# PIC32CM6408PL10048 device description
Architecture: CORTEX-M0PLUS; Family: PIC32CMPL; Series: PIC32CMPL10
Registers are 32-bit, read-write, reset 0x0 unless marked. A register's access mark holds for its fields unless they carry their own. Offsets are from the block's base; [hi:lo] are bit positions; lines under a group give offsets from that group; {n}, {i} and the like mark numbered series; 'fields as' and 'values as' point back to an identical list.

## PM — Power Manager
Instances: PM 0x40000400
0x04 SLEEPCFG — Sleep Configuration
  [2:0] SLEEPMODE
    2=IDLE (Idle sleep mode enabled); 4=STANDBY (Standby sleep mode enabled)
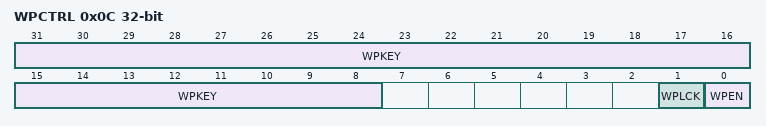
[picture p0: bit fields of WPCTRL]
0x0C WPCTRL — Write Protection Control
  [31:8] WPKEY — Write Protection Key
    0x505752=KEY (Allow writes to the WPCTRL register)
  [1] WPLCK — Write Protection Lock
  [0] WPEN — Write Protection Enable

## PORT — I/O Pin Controller
Instances: PORT 0x41000000, PORT_IOBUS 0x50000000
{0x0+0x80*i} GROUP[{i}] (i=0..1) group
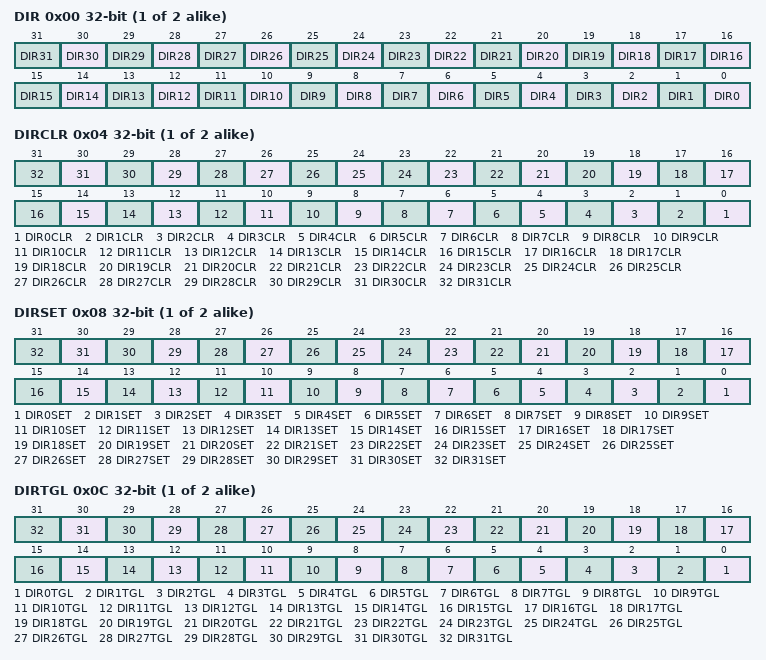
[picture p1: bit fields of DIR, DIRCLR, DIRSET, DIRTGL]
  0x00 DIR — Data Direction
    [n] DIR{n} (n=0..31) — Port Data Direction {n}
  0x04 DIRCLR (atomic clear of DIR) — Data Direction Clear
    [n] DIR{n}CLR (n=0..31) — Port Data Direction {n} Clear
  0x08 DIRSET (atomic set of DIR) — Data Direction Set
    [n] DIR{n}SET (n=0..31) — Port Data Direction {n} Set
  0x0C DIRTGL (atomic toggle of DIR) — Data Direction Toggle
    [n] DIR{n}TGL (n=0..31) — Port Data Direction {n} Toggle
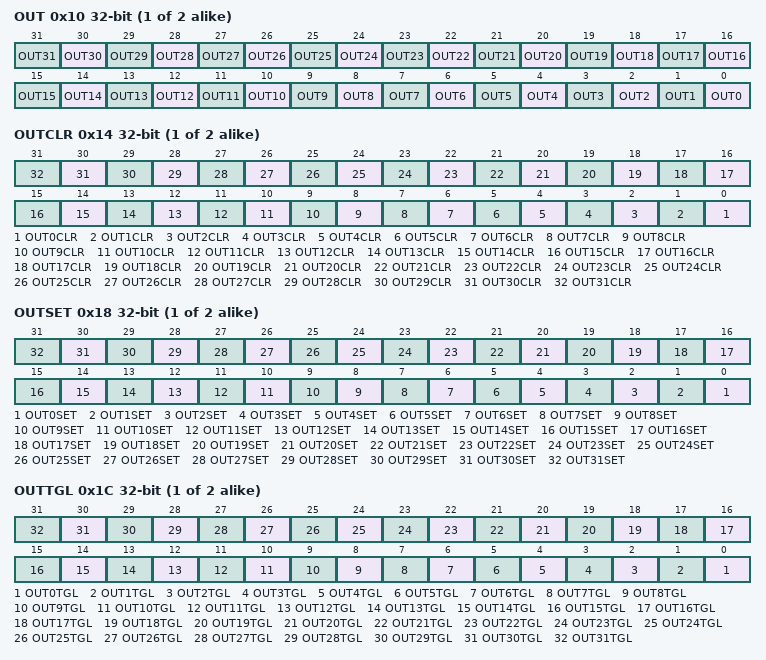
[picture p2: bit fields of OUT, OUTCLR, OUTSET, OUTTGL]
  0x10 OUT — Data Output Value
    [n] OUT{n} (n=0..31) — PORT Data Output Value {n}
  0x14 OUTCLR (atomic clear of OUT) — Data Output Value Clear
    [n] OUT{n}CLR (n=0..31) — PORT Data Output Value {n} Clear
  0x18 OUTSET (atomic set of OUT) — Data Output Value Set
    [n] OUT{n}SET (n=0..31) — PORT Data Output Value {n} Set
  0x1C OUTTGL (atomic toggle of OUT) — Data Output Value Toggle
    [n] OUT{n}TGL (n=0..31) — PORT Data Output Value {n} Toggle
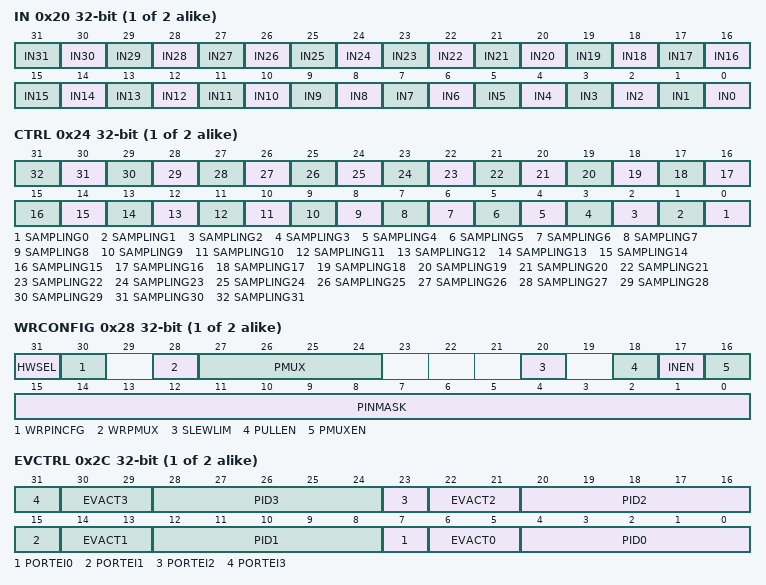
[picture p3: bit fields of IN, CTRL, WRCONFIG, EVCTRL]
  0x20 IN ro — Data Input Value
    [n] IN{n} (n=0..31) — PORT Data Input Value {n}
  0x24 CTRL — Control
    [n] SAMPLING{n} (n=0..31) — Input Sampling Mode {n}
  0x28 WRCONFIG wo — Write Configuration
    [31] HWSEL — Half-Word Select
    [30] WRPINCFG — Write PINCFG
    [28] WRPMUX — Write PMUX
    [27:24] PMUX — Peripheral Multiplexing
      0=A (Peripheral function A selected); 1=B (Peripheral function B selected); 2=C (Peripheral function C selected); 3=D (Peripheral function D selected); 4=E (Peripheral function E selected); 5=F (Peripheral function F selected); 6=G (Peripheral function G selected); 7=H (Peripheral function H selected); 8=I (Peripheral function I selected); 9=J (Peripheral function J selected)
    [20] SLEWLIM — Output Driver Slew Rate Limit Enable
    [18] PULLEN — Pull Enable
    [17] INEN — Input Enable
    [16] PMUXEN — Peripheral Multiplexer Enable
    [15:0] PINMASK — Pin Mask for Multiple Pin Configuration
  0x2C EVCTRL — Event Control
    [8n+7] PORTEI{n} (n=0..3) — PORT Event {n} Input Enable
    [8n+6:8n+5] EVACT{n} (n=0..3) — Event {n} Action
      0=OUT (The output value of pin PIDn will be set to the level of the event); 1=SET (Set the output value of pin PIDn on the rising edge of the event); 2=CLR (Clear the output value of pin PIDn on the rising edge of the event); 3=TGL (Toggle the output value of pin PIDn on the rising edge of the event)
    [8n+4:8n] PID{n} (n=0..3) — Event {n} Pin Identifier
      {v}=PIN{v} (Event actions will be executed on pin {v}) (v=0..31)
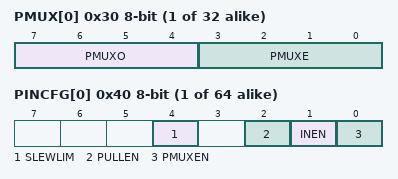
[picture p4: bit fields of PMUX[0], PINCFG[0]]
  {0x30+j} PMUX[{j}] (j=0..15) 8-bit — Peripheral Multiplexing #
    [7:4] PMUXO — Peripheral Multiplexing for Odd-Numbered Pin
      values as GROUP[0].WRCONFIG.PMUX
    [3:0] PMUXE — Peripheral Multiplexing for Even-Numbered Pin
      values as GROUP[0].WRCONFIG.PMUX
  {0x40+j} PINCFG[{j}] (j=0..31) 8-bit — Pin Configuration #
    [4] SLEWLIM — Output Driver Slew Rate Limit Enable
    [2] PULLEN — Pull Enable
    [1] INEN — Input Buffer Enable
    [0] PMUXEN — Peripheral Multiplexer Enable

## RSTC — Reset Controller
Instances: RSTC 0x40000C00
0x00 CTRLA — Control A
  [8] RSTPINDIS — Reset Pin Disable
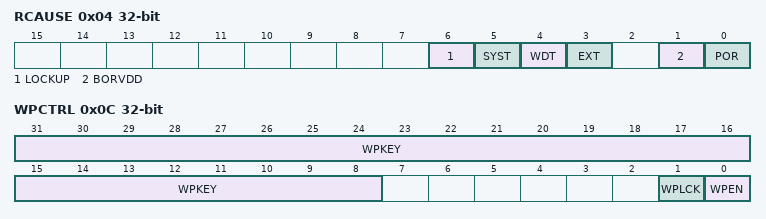
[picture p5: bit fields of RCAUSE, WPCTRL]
0x04 RCAUSE ro reset not defined — Reset Cause
  [6] LOCKUP — Software Reset Flag
  [5] SYST — System Reset Flag
  [4] WDT — Watchdog Reset Flag
  [3] EXT — External Reset Flag
  [1] BORVDD — VDD Brownout Reset Flag
  [0] POR — Power-On Reset Flag
0x08 DBGCTRL — Debug Control
  [0] LCKUPDIS — Lockup Disable
0x0C WPCTRL — Write Protection Control
  [31:8] WPKEY — Write Protection Key
    0x525354=KEY (Allow writes to the WPCTRL register)
  [1] WPLCK — Write Protection Lock
  [0] WPEN — Write Protection Enable

## Notices in the file
Copyright (c) 2025 Microchip Technology Inc.
SPDX-License-Identifier: Apache-2.0
Licensed under the Apache License, Version 2.0 (the "License");
you may not use this file except in compliance with the License.
You may obtain a copy of the License at
http://www.apache.org/licenses/LICENSE-2.0
Unless required by applicable law or agreed to in writing, software
distributed under the License is distributed on an "AS IS" BASIS,
WITHOUT WARRANTIES OR CONDITIONS OF ANY KIND, either express or implied.
See the License for the specific language governing permissions and
limitations under the License.
